VERSION ""

NS_ :

BS_:

BU_: ELC ZGW

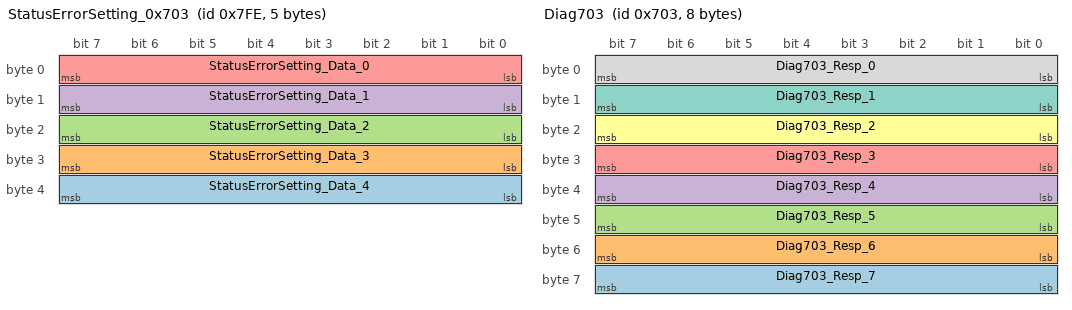
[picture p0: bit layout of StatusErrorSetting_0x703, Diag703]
BO_ 2046 StatusErrorSetting_0x703: 5 ELC
 SG_ StatusErrorSetting_Data_4 : 32|8@1+ (1,0) [0|255] ""  ZGW
 SG_ StatusErrorSetting_Data_3 : 24|8@1+ (1,0) [0|255] ""  ZGW
 SG_ StatusErrorSetting_Data_2 : 16|8@1+ (1,0) [0|255] ""  ZGW
 SG_ StatusErrorSetting_Data_1 : 8|8@1+ (1,0) [0|255] ""  ZGW
 SG_ StatusErrorSetting_Data_0 : 0|8@1+ (1,0) [0|255] ""  ZGW

BO_ 1023 Networkmanagement3_RequestStatus: 1 ZGW
 SG_ NM3RS_PN1 : 0|8@1+ (1,0) [0|255] ""  ELC

BO_ 1795 Diag703: 8 ZGW
 SG_ Diag703_Resp_7 : 56|8@1+ (1,0) [0|255] ""  ZGW
 SG_ Diag703_Resp_6 : 48|8@1+ (1,0) [0|255] ""  ZGW
 SG_ Diag703_Resp_5 : 40|8@1+ (1,0) [0|255] ""  ZGW
 SG_ Diag703_Resp_4 : 32|8@1+ (1,0) [0|255] ""  ZGW
 SG_ Diag703_Resp_3 : 24|8@1+ (1,0) [0|255] ""  ZGW
 SG_ Diag703_Resp_2 : 16|8@1+ (1,0) [0|255] ""  ZGW
 SG_ Diag703_Resp_1 : 8|8@1+ (1,0) [0|255] ""  ZGW
 SG_ Diag703_Resp_0 : 0|8@1+ (1,0) [0|255] ""  ZGW

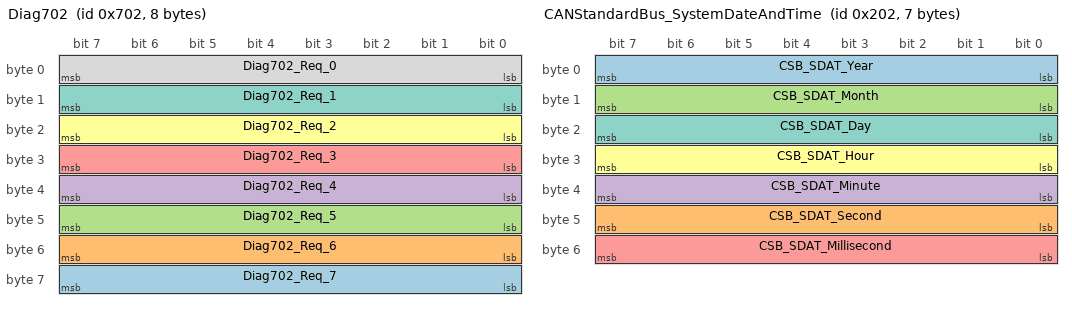
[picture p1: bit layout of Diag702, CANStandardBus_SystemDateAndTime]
BO_ 1794 Diag702: 8 ZGW
 SG_ Diag702_Req_7 : 56|8@1+ (1,0) [0|255] ""  ELC
 SG_ Diag702_Req_6 : 48|8@1+ (1,0) [0|255] ""  ELC
 SG_ Diag702_Req_5 : 40|8@1+ (1,0) [0|255] ""  ELC
 SG_ Diag702_Req_4 : 32|8@1+ (1,0) [0|255] ""  ELC
 SG_ Diag702_Req_3 : 24|8@1+ (1,0) [0|255] ""  ELC
 SG_ Diag702_Req_2 : 16|8@1+ (1,0) [0|255] ""  ELC
 SG_ Diag702_Req_1 : 8|8@1+ (1,0) [0|255] ""  ELC
 SG_ Diag702_Req_0 : 0|8@1+ (1,0) [0|255] ""  ELC

BO_ 514 CANStandardBus_SystemDateAndTime: 7 ZGW
 SG_ CSB_SDAT_Year : 0|8@1+ (1,0) [0|255] ""  ELC
 SG_ CSB_SDAT_Second : 40|8@1+ (1,0) [0|255] ""  ELC
 SG_ CSB_SDAT_Month : 8|8@1+ (1,0) [0|255] ""  ELC
 SG_ CSB_SDAT_Minute : 32|8@1+ (1,0) [0|255] ""  ELC
 SG_ CSB_SDAT_Millisecond : 48|8@1+ (1,0) [0|255] ""  ELC
 SG_ CSB_SDAT_Hour : 24|8@1+ (1,0) [0|255] ""  ELC
 SG_ CSB_SDAT_Day : 16|8@1+ (1,0) [0|255] ""  ELC

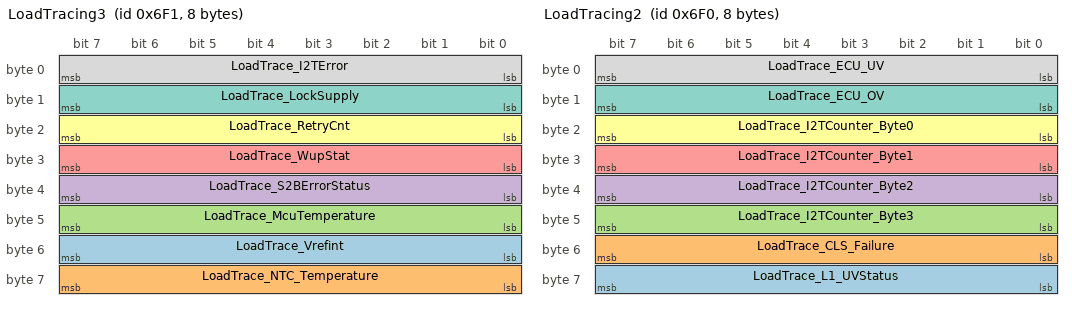
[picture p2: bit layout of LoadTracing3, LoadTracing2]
BO_ 1777 LoadTracing3: 8 ELC
 SG_ LoadTrace_Vrefint : 48|8@1+ (1,0) [0|255] "" Vector__XXX
 SG_ LoadTrace_NTC_Temperature : 56|8@1+ (1,0) [0|255] "" Vector__XXX
 SG_ LoadTrace_McuTemperature : 40|8@1+ (1,0) [0|255] "" Vector__XXX
 SG_ LoadTrace_S2BErrorStatus : 32|8@1+ (1,0) [0|255] "" Vector__XXX
 SG_ LoadTrace_WupStat : 24|8@1+ (1,0) [0|255] ""  ZGW
 SG_ LoadTrace_RetryCnt : 16|8@1+ (1,0) [0|255] ""  ZGW
 SG_ LoadTrace_LockSupply : 8|8@1+ (1,0) [0|255] ""  ZGW
 SG_ LoadTrace_I2TError : 0|8@1+ (1,0) [0|255] ""  ZGW

BO_ 1776 LoadTracing2: 8 ELC
 SG_ LoadTrace_L1_UVStatus : 56|8@1+ (1,0) [0|255] ""  ZGW
 SG_ LoadTrace_CLS_Failure : 48|8@1+ (1,0) [0|255] ""  ZGW
 SG_ LoadTrace_I2TCounter_Byte3 : 40|8@1+ (1,0) [0|255] ""  ZGW
 SG_ LoadTrace_I2TCounter_Byte2 : 32|8@1+ (1,0) [0|255] ""  ZGW
 SG_ LoadTrace_I2TCounter_Byte1 : 24|8@1+ (1,0) [0|255] ""  ZGW
 SG_ LoadTrace_I2TCounter_Byte0 : 16|8@1+ (1,0) [0|255] ""  ZGW
 SG_ LoadTrace_ECU_OV : 8|8@1+ (1,0) [0|255] ""  ZGW
 SG_ LoadTrace_ECU_UV : 0|8@1+ (1,0) [0|255] ""  ZGW

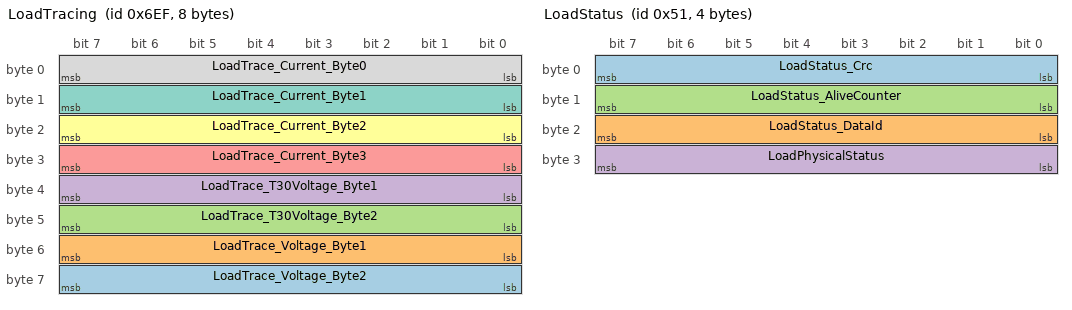
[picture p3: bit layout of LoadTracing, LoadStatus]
BO_ 1775 LoadTracing: 8 ELC
 SG_ LoadTrace_Voltage_Byte2 : 56|8@1+ (1,0) [0|255] ""  ZGW
 SG_ LoadTrace_Voltage_Byte1 : 48|8@1+ (1,0) [0|255] ""  ZGW
 SG_ LoadTrace_T30Voltage_Byte2 : 40|8@1+ (1,0) [0|255] ""  ZGW
 SG_ LoadTrace_T30Voltage_Byte1 : 32|8@1+ (1,0) [0|255] ""  ZGW
 SG_ LoadTrace_Current_Byte3 : 24|8@1+ (1,0) [0|255] ""  ZGW
 SG_ LoadTrace_Current_Byte2 : 16|8@1+ (1,0) [0|255] ""  ZGW
 SG_ LoadTrace_Current_Byte1 : 8|8@1+ (1,0) [0|255] ""  ZGW
 SG_ LoadTrace_Current_Byte0 : 0|8@1+ (1,0) [0|255] ""  ZGW

BO_ 81 LoadStatus: 4 ELC
 SG_ LoadStatus_Crc : 0|8@1+ (1,0) [0|255] "" Vector__XXX
 SG_ LoadStatus_DataId : 16|8@1+ (1,0) [0|255] "" Vector__XXX
 SG_ LoadStatus_AliveCounter : 8|8@1+ (1,0) [0|15] "" Vector__XXX
 SG_ LoadPhysicalStatus : 24|8@1+ (1,0) [0|255] ""  ZGW

BO_ 80 LoadRequest: 1 ZGW
 SG_ LoadStatusRequest : 0|8@1+ (1,0) [0|255] ""  ELC

BA_DEF_  "BusType" STRING ;
BA_DEF_DEF_  "BusType" "CAN";
